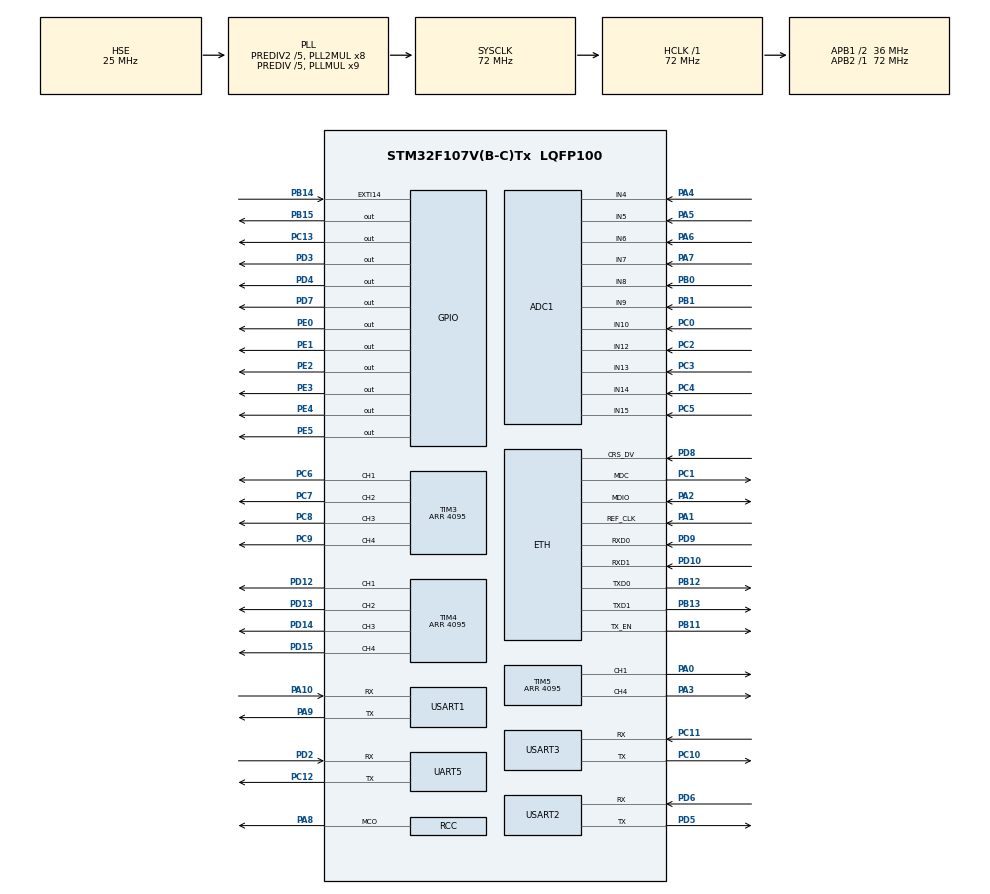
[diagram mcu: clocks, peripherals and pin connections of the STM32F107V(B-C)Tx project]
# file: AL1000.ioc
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ADC1.Channel-0\#ChannelRegularConversion=ADC_CHANNEL_4
ADC1.NbrOfConversionFlag=1
ADC1.Rank-0\#ChannelRegularConversion=1
ADC1.SamplingTime-0\#ChannelRegularConversion=ADC_SAMPLETIME_1CYCLE_5
ADC1.master=1
ETH.MediaInterface=ETH_MEDIA_INTERFACE_RMII
ETH.PHY_CONFIG_DELAY=4095
ETH.PHY_Name_RMII=DP83848_PHY_ADDRESS
ETH.PHY_READ_TO=65535
ETH.PHY_RESET_DELAY=255
ETH.PHY_WRITE_TO=65535
LWIP.CHECKSUM_BY_HARDWARE=0
LWIP.IP_ADDRESS=192.100.000.000
LWIP.LWIP_DHCP=0
LWIP.LWIP_HTTPD=0
LWIP.LWIP_ICMP=1
LWIP.LWIP_NETIF_LINK_CALLBACK=1
LWIP.LWIP_NETIF_STATUS_CALLBACK=1
LWIP.LWIP_STATS=0
LWIP.LWIP_TIMERS=1
LWIP.MEMP_NUM_PBUF=8
LWIP.MEMP_NUM_TCP_PCB=20
LWIP.MEMP_NUM_TCP_PCB_LISTEN=5
LWIP.MEMP_NUM_TCP_SEG=10
LWIP.MEMP_NUM_UDP_PCB=6
LWIP.Version=v2.0.0_Cube
Mcu.Family=STM32F1
Mcu.Name=STM32F107V(B-C)Tx
Mcu.Package=LQFP100
NVIC.ETH_IRQn=true\:0\:0\:false\:false\:true\:true\:true
NVIC.EXTI15_10_IRQn=true\:0\:0\:false\:false\:true\:true\:true
NVIC.PriorityGroup=NVIC_PRIORITYGROUP_4
NVIC.UART5_IRQn=true\:0\:0\:false\:false\:true\:true\:true
NVIC.USART1_IRQn=true\:0\:0\:false\:false\:true\:true\:true
NVIC.USART2_IRQn=true\:0\:0\:false\:false\:true\:true\:true
NVIC.USART3_IRQn=true\:0\:0\:false\:false\:true\:true\:true
OSC_IN.Mode=HSE-External-Clock-Source
OSC_IN.Signal=RCC_OSC_IN
OSC_OUT.Mode=HSE-External-Clock-Source
OSC_OUT.Signal=RCC_OSC_OUT
PA0-WKUP.Signal=S_TIM5_CH1
PA1.Mode=RMII
PA1.Signal=ETH_REF_CLK
PA10.Mode=Asynchronous
PA10.Signal=USART1_RX
PA13.Mode=Serial_Wire
PA13.Signal=SYS_JTMS-SWDIO
PA14.Mode=Serial_Wire
PA14.Signal=SYS_JTCK-SWCLK
PA2.Mode=RMII
PA2.Signal=ETH_MDIO
PA3.Signal=S_TIM5_CH4
PA4.Signal=ADCx_IN4
PA5.Signal=ADCx_IN5
PA6.Signal=ADCx_IN6
PA7.Signal=ADCx_IN7
PA8.GPIO_Speed=GPIO_SPEED_FREQ_HIGH
PA8.Mode=Clock-out
PA8.Signal=RCC_MCO
PA9.Mode=Asynchronous
PA9.Signal=USART1_TX
PB0.Signal=ADCx_IN8
PB1.Signal=ADCx_IN9
PB11.Mode=RMII
PB11.Signal=ETH_TX_EN
PB12.Mode=RMII
PB12.Signal=ETH_TXD0
PB13.Mode=RMII
PB13.Signal=ETH_TXD1
PB14.GPIO_ModeDefaultEXTI=GPIO_MODE_IT_FALLING
PB14.Signal=GPXTI14
PB15.PinState=GPIO_PIN_SET
PB15.Signal=GPIO_Output
PC0.Signal=ADCx_IN10
PC1.Mode=RMII
PC1.Signal=ETH_MDC
PC10.Mode=Asynchronous
PC10.Signal=USART3_TX
PC11.Mode=Asynchronous
PC11.Signal=USART3_RX
PC12.Mode=Asynchronous
PC12.Signal=UART5_TX
PC13-TAMPER-RTC.PinState=GPIO_PIN_SET
PC13-TAMPER-RTC.Signal=GPIO_Output
PC2.Signal=ADCx_IN12
PC3.Signal=ADCx_IN13
PC4.Signal=ADCx_IN14
PC5.Signal=ADCx_IN15
PC6.GPIO_Speed=GPIO_SPEED_FREQ_HIGH
PC6.Signal=S_TIM3_CH1
PC7.GPIO_Speed=GPIO_SPEED_FREQ_HIGH
PC7.Signal=S_TIM3_CH2
PC8.GPIO_Speed=GPIO_SPEED_FREQ_HIGH
PC8.Signal=S_TIM3_CH3
PC9.GPIO_Speed=GPIO_SPEED_FREQ_HIGH
PC9.Signal=S_TIM3_CH4
PD10.Mode=RMII
PD10.Signal=ETH_RXD1
PD12.GPIO_Speed=GPIO_SPEED_FREQ_HIGH
PD12.Signal=S_TIM4_CH1
PD13.GPIO_Speed=GPIO_SPEED_FREQ_HIGH
PD13.Signal=S_TIM4_CH2
PD14.GPIO_Speed=GPIO_SPEED_FREQ_HIGH
PD14.Signal=S_TIM4_CH3
PD15.GPIO_Speed=GPIO_SPEED_FREQ_HIGH
PD15.Signal=S_TIM4_CH4
PD2.Mode=Asynchronous
PD2.Signal=UART5_RX
PD3.PinState=GPIO_PIN_SET
PD3.Signal=GPIO_Output
PD4.PinState=GPIO_PIN_SET
PD4.Signal=GPIO_Output
PD5.Mode=Asynchronous
PD5.Signal=USART2_TX
PD6.Mode=Asynchronous
PD6.Signal=USART2_RX
PD7.PinState=GPIO_PIN_SET
PD7.Signal=GPIO_Output
PD8.Mode=RMII
PD8.Signal=ETH_CRS_DV
PD9.Mode=RMII
PD9.Signal=ETH_RXD0
PE0.GPIO_ModeDefaultOutputPP=GPIO_MODE_OUTPUT_PP
PE0.GPIO_Speed=GPIO_SPEED_FREQ_LOW
PE0.PinState=GPIO_PIN_SET
PE0.Signal=GPIO_Output
PE1.PinState=GPIO_PIN_SET
PE1.Signal=GPIO_Output
PE2.PinState=GPIO_PIN_SET
PE2.Signal=GPIO_Output
PE3.PinState=GPIO_PIN_SET
PE3.Signal=GPIO_Output
PE4.PinState=GPIO_PIN_SET
PE4.Signal=GPIO_Output
PE5.PinState=GPIO_PIN_SET
PE5.Signal=GPIO_Output
ProjectManager.HeapSize=0x200
ProjectManager.StackSize=0x400
ProjectManager.TargetToolchain=SW4STM32
RCC.ADCPresc=RCC_ADCPCLK2_DIV6
RCC.AHBFreq_Value=72000000
RCC.APB1CLKDivider=RCC_HCLK_DIV2
RCC.APB1Freq_Value=36000000
RCC.APB1TimFreq_Value=72000000
RCC.APB2Freq_Value=72000000
RCC.APB2TimFreq_Value=72000000
RCC.HCLKFreq_Value=72000000
RCC.HSEDivPLL=RCC_HSE_PREDIV_DIV5
RCC.HSE_VALUE=25000000
RCC.PLL3Mul=RCC_PLLI2S_MUL10
RCC.PLLMUL=RCC_PLL_MUL9
RCC.PLLSourceVirtual=RCC_PLLSOURCE_HSE
RCC.Prediv1Source=RCC_PREDIV1_SOURCE_PLL2
RCC.Prediv2=RCC_HSE_PREDIV2_DIV5
RCC.RCC_MCOSource=RCC_MCO1SOURCE_PLL3CLK
RCC.SYSCLKFreq_VALUE=72000000
RCC.SYSCLKSource=RCC_SYSCLKSOURCE_PLLCLK
RCC.USBFreq_Value=48000000
SH.ADCx_IN10.0=ADC1_IN10,IN10
SH.ADCx_IN12.0=ADC1_IN12,IN12
SH.ADCx_IN13.0=ADC1_IN13,IN13
SH.ADCx_IN14.0=ADC1_IN14,IN14
SH.ADCx_IN15.0=ADC1_IN15,IN15
SH.ADCx_IN4.0=ADC1_IN4,IN4
SH.ADCx_IN5.0=ADC1_IN5,IN5
SH.ADCx_IN6.0=ADC1_IN6,IN6
SH.ADCx_IN7.0=ADC1_IN7,IN7
SH.ADCx_IN8.0=ADC1_IN8,IN8
SH.ADCx_IN9.0=ADC1_IN9,IN9
SH.S_TIM3_CH1.0=TIM3_CH1,PWM Generation1 CH1
SH.S_TIM3_CH2.0=TIM3_CH2,PWM Generation2 CH2
SH.S_TIM3_CH3.0=TIM3_CH3,PWM Generation3 CH3
SH.S_TIM3_CH4.0=TIM3_CH4,PWM Generation4 CH4
SH.S_TIM4_CH1.0=TIM4_CH1,PWM Generation1 CH1
SH.S_TIM4_CH2.0=TIM4_CH2,PWM Generation2 CH2
SH.S_TIM4_CH3.0=TIM4_CH3,PWM Generation3 CH3
SH.S_TIM4_CH4.0=TIM4_CH4,PWM Generation4 CH4
SH.S_TIM5_CH1.0=TIM5_CH1,PWM Generation1 CH1
SH.S_TIM5_CH4.0=TIM5_CH4,PWM Generation4 CH4
TIM3.AutoReloadPreload=TIM_AUTORELOAD_PRELOAD_ENABLE
TIM3.Channel-PWM\ Generation1\ CH1=TIM_CHANNEL_1
TIM3.Channel-PWM\ Generation2\ CH2=TIM_CHANNEL_2
TIM3.Channel-PWM\ Generation3\ CH3=TIM_CHANNEL_3
TIM3.Channel-PWM\ Generation4\ CH4=TIM_CHANNEL_4
TIM3.Period=4095
TIM4.AutoReloadPreload=TIM_AUTORELOAD_PRELOAD_ENABLE
TIM4.Channel-PWM\ Generation1\ CH1=TIM_CHANNEL_1
TIM4.Channel-PWM\ Generation2\ CH2=TIM_CHANNEL_2
TIM4.Channel-PWM\ Generation3\ CH3=TIM_CHANNEL_3
TIM4.Channel-PWM\ Generation4\ CH4=TIM_CHANNEL_4
TIM4.Period=4095
TIM5.AutoReloadPreload=TIM_AUTORELOAD_PRELOAD_ENABLE
TIM5.Channel-PWM\ Generation1\ CH1=TIM_CHANNEL_1
TIM5.Channel-PWM\ Generation4\ CH4=TIM_CHANNEL_4
TIM5.Period=4095
TIM5.Pulse-PWM\ Generation1\ CH1=0
UART5.VirtualMode=Asynchronous
USART1.VirtualMode=VM_ASYNC
USART2.VirtualMode=VM_ASYNC
USART3.VirtualMode=VM_ASYNC
VP_ADC1_TempSens_Input.Mode=IN-TempSens
VP_ADC1_Vref_Input.Mode=IN-Vrefint
VP_CRC_VS_CRC.Mode=CRC_Activate
VP_IWDG_VS_IWDG.Mode=IWDG_Activate
VP_LWIP_VS_Enabled.Mode=Enabled
VP_TIM3_VS_ClockSourceINT.Mode=Internal
VP_TIM4_VS_ClockSourceINT.Mode=Internal
VP_TIM5_VS_ClockSourceINT.Mode=Internal
board=AL1000

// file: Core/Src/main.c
/* USER CODE BEGIN Header */
/**
  ******************************************************************************
  * @file           : main.c
  * @brief          : Main program body
  ******************************************************************************
  * @attention
  *
  * <h2><center>&copy; Copyright (c) 2019 STMicroelectronics.
  * All rights reserved.</center></h2>
  *
  * This software component is licensed by ST under Ultimate Liberty license
  * SLA0044, the "License"; You may not use this file except in compliance with
  * the License. You may obtain a copy of the License at:
  *                             www.st.com/SLA0044
  *
  ******************************************************************************
  */
/* USER CODE END Header */

#include "main.h"
#include "adc.h"
#include "crc.h"
#include "iwdg.h"
#include "lwip.h"
#include "tim.h"
#include "usart.h"
#include "gpio.h"

/* USER CODE BEGIN Includes */
#include "config.h"
#include "serial.h"
#include "modbus.h"
#include "gl_696h.h"
/* USER CODE END Includes */

void SystemClock_Config(void);

int main(void)
{

  /* MCU Configuration--------------------------------------------------------*/

  /* Reset of all peripherals, Initializes the Flash interface and the Systick. */
  HAL_Init();

  /* Configure the system clock */
  SystemClock_Config();

  /* Initialize all configured peripherals */
  MX_GPIO_Init();
//  MX_LWIP_Init();
//  MX_IWDG_Init();
  MX_TIM5_Init();
  MX_TIM3_Init();
  MX_TIM4_Init();
  MX_ADC1_Init();
  MX_USART1_UART_Init();
  MX_USART2_UART_Init();
  MX_USART3_UART_Init();
  MX_UART5_Init();
  MX_CRC_Init();
  /* USER CODE BEGIN 2 */
  AL1000_Init();

  /* USER CODE END 2 */

  /* Infinite loop */
  /* USER CODE BEGIN WHILE */
  while (1)
  {
	//HAL_IWDG_Refresh(&hiwdg);

    /* USER CODE END WHILE */

    /* USER CODE BEGIN 3 */
	MX_LWIP_Process();
	AL1000_Task();
  }
  /* USER CODE END 3 */
}

void SystemClock_Config(void)
{
  RCC_OscInitTypeDef RCC_OscInitStruct = {0};
  RCC_ClkInitTypeDef RCC_ClkInitStruct = {0};
  RCC_PeriphCLKInitTypeDef PeriphClkInit = {0};

  /** Initializes the CPU, AHB and APB busses clocks
  */
  RCC_OscInitStruct.OscillatorType = RCC_OSCILLATORTYPE_LSI|RCC_OSCILLATORTYPE_HSE;
  RCC_OscInitStruct.HSEState = RCC_HSE_BYPASS;
  RCC_OscInitStruct.HSEPredivValue = RCC_HSE_PREDIV_DIV5;
  RCC_OscInitStruct.HSIState = RCC_HSI_ON;
  RCC_OscInitStruct.LSIState = RCC_LSI_ON;
  RCC_OscInitStruct.Prediv1Source = RCC_PREDIV1_SOURCE_PLL2;
  RCC_OscInitStruct.PLL.PLLState = RCC_PLL_ON;
  RCC_OscInitStruct.PLL.PLLSource = RCC_PLLSOURCE_HSE;
  RCC_OscInitStruct.PLL.PLLMUL = RCC_PLL_MUL9;
  RCC_OscInitStruct.PLL2.PLL2State = RCC_PLL2_ON;
  RCC_OscInitStruct.PLL2.PLL2MUL = RCC_PLL2_MUL8;
  RCC_OscInitStruct.PLL2.HSEPrediv2Value = RCC_HSE_PREDIV2_DIV5;
  if (HAL_RCC_OscConfig(&RCC_OscInitStruct) != HAL_OK)
  {
    Error_Handler();
  }
  /** Initializes the CPU, AHB and APB busses clocks
  */
  RCC_ClkInitStruct.ClockType = RCC_CLOCKTYPE_HCLK|RCC_CLOCKTYPE_SYSCLK
                              |RCC_CLOCKTYPE_PCLK1|RCC_CLOCKTYPE_PCLK2;
  RCC_ClkInitStruct.SYSCLKSource = RCC_SYSCLKSOURCE_PLLCLK;
  RCC_ClkInitStruct.AHBCLKDivider = RCC_SYSCLK_DIV1;
  RCC_ClkInitStruct.APB1CLKDivider = RCC_HCLK_DIV2;
  RCC_ClkInitStruct.APB2CLKDivider = RCC_HCLK_DIV1;

  if (HAL_RCC_ClockConfig(&RCC_ClkInitStruct, FLASH_LATENCY_2) != HAL_OK)
  {
    Error_Handler();
  }
  PeriphClkInit.PeriphClockSelection = RCC_PERIPHCLK_ADC;
  PeriphClkInit.AdcClockSelection = RCC_ADCPCLK2_DIV6;
  PeriphClkInit.PLLI2S.PLLI2SMUL = RCC_PLLI2S_MUL10;
  PeriphClkInit.PLLI2S.HSEPrediv2Value = RCC_HSE_PREDIV2_DIV5;
  if (HAL_RCCEx_PeriphCLKConfig(&PeriphClkInit) != HAL_OK)
  {
    Error_Handler();
  }
  HAL_RCC_MCOConfig(RCC_MCO, RCC_MCO1SOURCE_PLL3CLK, RCC_MCODIV_1);
  /** Configure the Systick interrupt time
  */
  __HAL_RCC_HSE_PREDIV2_CONFIG(RCC_HSE_PREDIV2_DIV5);
  /** Configure the Systick interrupt time
  */
  __HAL_RCC_PLLI2S_CONFIG(RCC_PLLI2S_MUL10);
  /** Configure the Systick interrupt time
  */
  __HAL_RCC_PLLI2S_ENABLE();
}

void Error_Handler(void)
{
  /* USER CODE BEGIN Error_Handler_Debug */
  /* User can add his own implementation to report the HAL error return state */
	//printf("%s %ld\r\n",file,line);
  /* USER CODE END Error_Handler_Debug */
}

#ifdef  USE_FULL_ASSERT
/**
  * @brief  Reports the name of the source file and the source line number
  *         where the assert_param error has occurred.
  * @param  file: pointer to the source file name
  * @param  line: assert_param error line source number
  * @retval None
  */
void assert_failed(uint8_t *file, uint32_t line)
{
  /* USER CODE BEGIN 6 */
  /* User can add his own implementation to report the file name and line number,
     tex: printf("Wrong parameters value: file %s on line %d\r\n", file, line) */
	  printf("%s %ld\r\n",file,line);
	  while(1);
  /* USER CODE END 6 */
}
#endif /* USE_FULL_ASSERT */

/************************ (C) COPYRIGHT STMicroelectronics *****END OF FILE****/
